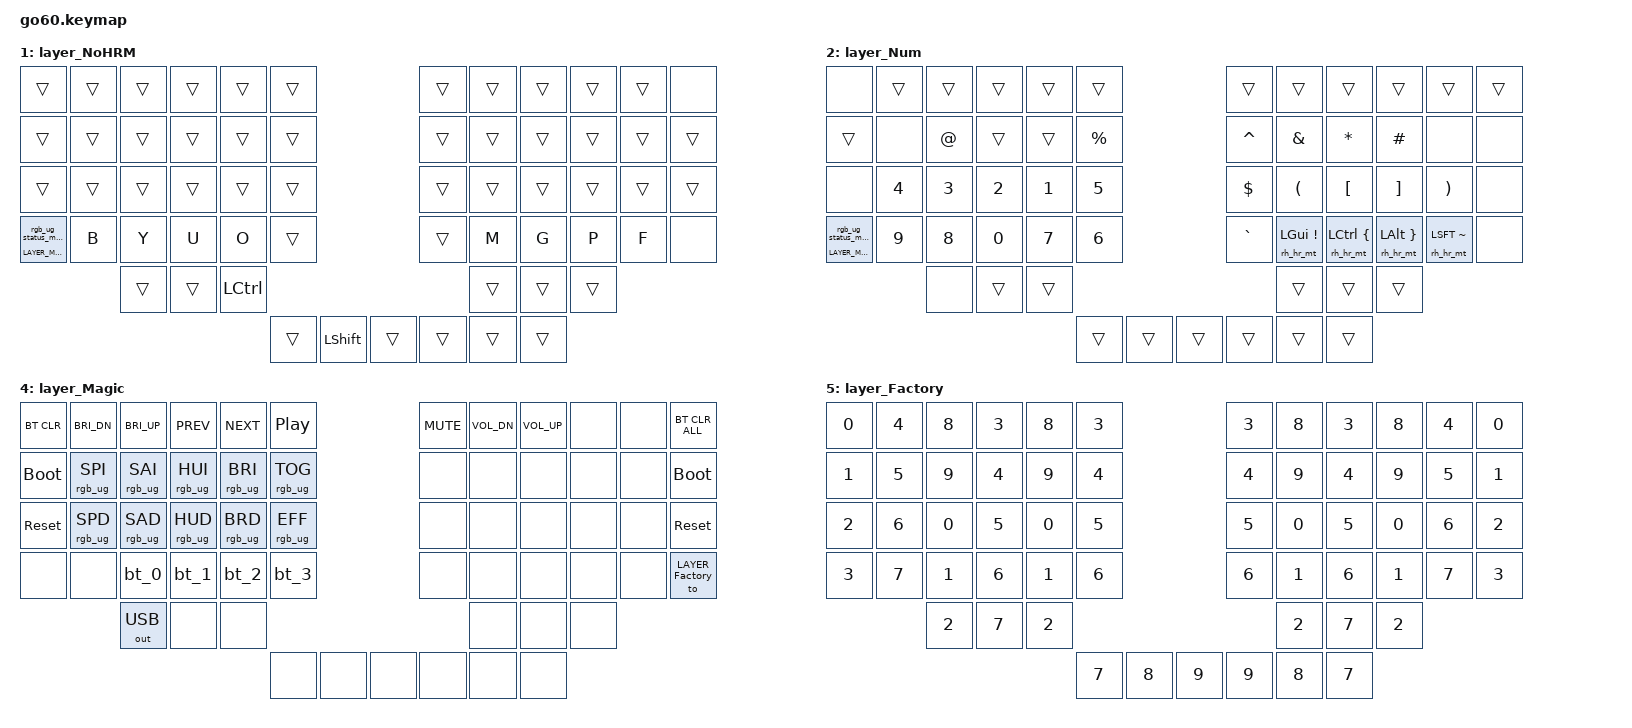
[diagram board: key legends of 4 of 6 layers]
/*
 * Copyright (c) 2020 The ZMK Contributors
 *
 * SPDX-License-Identifier: MIT
 */

#include <behaviors.dtsi>

#include <dt-bindings/zmk/bt.h>
#include <dt-bindings/zmk/ext_power.h>
#include <dt-bindings/zmk/keys.h>
#include <dt-bindings/zmk/outputs.h>
#include <dt-bindings/zmk/rgb.h>
#include <dt-bindings/zmk/input_transform.h>
#include <dt-bindings/zmk/pointing.h>

#include <input/processors.dtsi>
#include <zephyr/dt-bindings/input/input-event-codes.h>

/* Key positions */

#define POS_LH_C6R1 0
#define POS_LH_C5R1 1
#define POS_LH_C4R1 2
#define POS_LH_C3R1 3
#define POS_LH_C2R1 4
#define POS_LH_C1R1 5
#define POS_RH_C1R1 6
#define POS_RH_C2R1 7
#define POS_RH_C3R1 8
#define POS_RH_C4R1 9
#define POS_RH_C5R1 10
#define POS_RH_C6R1 11
#define POS_LH_C6R2 12
#define POS_LH_C5R2 13
#define POS_LH_C4R2 14
#define POS_LH_C3R2 15
#define POS_LH_C2R2 16
#define POS_LH_C1R2 17
#define POS_RH_C1R2 18
#define POS_RH_C2R2 19
#define POS_RH_C3R2 20
#define POS_RH_C4R2 21
#define POS_RH_C5R2 22
#define POS_RH_C6R2 23
#define POS_LH_C6R3 24
#define POS_LH_C5R3 25
#define POS_LH_C4R3 26
#define POS_LH_C3R3 27
#define POS_LH_C2R3 28
#define POS_LH_C1R3 29
#define POS_RH_C1R3 30
#define POS_RH_C2R3 31
#define POS_RH_C3R3 32
#define POS_RH_C4R3 33
#define POS_RH_C5R3 34
#define POS_RH_C6R3 35
#define POS_LH_C6R4 36
#define POS_LH_C5R4 37
#define POS_LH_C4R4 38
#define POS_LH_C3R4 39
#define POS_LH_C2R4 40
#define POS_LH_C1R4 41
#define POS_RH_C1R4 42
#define POS_RH_C2R4 43
#define POS_RH_C3R4 44
#define POS_RH_C4R4 45
#define POS_RH_C5R4 46
#define POS_RH_C6R4 47
#define POS_LH_C4R5 48
#define POS_LH_C3R5 49
#define POS_LH_C2R5 50
#define POS_RH_C2R5 51
#define POS_RH_C3R5 52
#define POS_RH_C4R5 53
#define POS_LH_T1 54
#define POS_LH_T2 55
#define POS_LH_T3 56
#define POS_RH_T3 57
#define POS_RH_T2 58
#define POS_RH_T1 59


#define LEFT_HAND_KEYS \
  POS_LH_C1R1 POS_LH_C2R1 POS_LH_C3R1 POS_LH_C4R1 POS_LH_C5R1 POS_LH_C6R1 \
  POS_LH_C1R2 POS_LH_C2R2 POS_LH_C3R2 POS_LH_C4R2 POS_LH_C5R2 POS_LH_C6R2 \
  POS_LH_C1R3 POS_LH_C2R3 POS_LH_C3R3 POS_LH_C4R3 POS_LH_C5R3 POS_LH_C6R3 \
  POS_LH_C1R4 POS_LH_C2R4 POS_LH_C3R4 POS_LH_C4R4 POS_LH_C5R4 POS_LH_C6R4 \
              POS_LH_C2R5 POS_LH_C3R5 POS_LH_C4R5

#define RIGHT_HAND_KEYS \
  POS_RH_C1R1 POS_RH_C2R1 POS_RH_C3R1 POS_RH_C4R1 POS_RH_C5R1 POS_RH_C6R1 \
  POS_RH_C1R2 POS_RH_C2R2 POS_RH_C3R2 POS_RH_C4R2 POS_RH_C5R2 POS_RH_C6R2 \
  POS_RH_C1R3 POS_RH_C2R3 POS_RH_C3R3 POS_RH_C4R3 POS_RH_C5R3 POS_RH_C6R3 \
  POS_RH_C1R4 POS_RH_C2R4 POS_RH_C3R4 POS_RH_C4R4 POS_RH_C5R4 POS_RH_C6R4 \
              POS_RH_C2R5 POS_RH_C3R5 POS_RH_C4R5

#define THUMB_KEYS \
  POS_LH_T1 POS_LH_T2 POS_LH_T3 \
  POS_RH_T1 POS_RH_T2 POS_RH_T3


// layers
#define LAYER_Base 0
#define LAYER_NoHRM 1
#define LAYER_Num 2
#define LAYER_Nav 3
#define LAYER_Magic 4
#define LAYER_Factory 5


/* Custom Defined Behaviors */
/ {
    /* How long Sticky Keys and Sticky Layers stay pressed */
#define STICKY_KEY_RELEASE_AFTER_MS 600

/* How quickly Combo keys must be pressed together */
#define COMBO_TIMEOUT_MS 45

/* How quickly both thumb Shift keys must be pressed together to activate Caps
   Word */
#define CAPS_WORD_COMBO_TIMEOUT_MS 150

/* How long to hold to activate home row mods for same side or mouse usage */
#define HOME_ROW_MODS_TAPPING_TERM_MS 300

/* Cool down after typing before home row mods can be used */
#define HOME_ROW_MODS_QUICK_TAP_MS 250

/* How long thumb keys can be held before rolls send the higher layer key */
#define THUMBS_TAPPING_TERM_MS 200

/* How quickly to double tap reaching thumb keys to hold down the tap action */
#define REACH_THUMBS_QUICK_TAP_MS 250

/* How long until each phase of the typing assist features times out */
#define TYPING_ASSIST_TIMEOUT_MS 60000

/* How long to hold for Autoshift */
#define AUTOSHIFT_TAPPING_TERM_MS 200

/* How long until the word and line selection feature times out */
#define SELECT_TIMEOUT_MS 60000

/* How quickly confirmation action keys must be double tapped to activate */
#define DOUBLE_TAP_TIMEOUT_MS 250


/* Convert NAME parameters into a ZMK label string */
#define STRINGIFY(x) #x

/* Create a ZMK Behavior without having to specify the name three times */
#define ZMK_BEHAVIOR(NAME, ...) \
    behaviors { \
        NAME: NAME { \
            label = STRINGIFY(ZB_ ## NAME); \
            __VA_ARGS__ \
        }; \
    };

/* Hold-Tap helper */
#define HOLD_TAP(NAME, ...) \
    ZMK_BEHAVIOR(NAME, \
        compatible = "zmk,behavior-hold-tap"; \
        #binding-cells = <2>; \
        __VA_ARGS__ \
    )

/* Balanced Hold-Tap for home row mods and thumb layer keys */
#define BALANCED_HOLD_TAP(NAME, ...) \
    HOLD_TAP(NAME, \
        flavor = "balanced";  /* Fast hold */ \
        __VA_ARGS__ \
    )

/* "Timerless" home row mod Hold-Tap using defined timers */
#define HOME_ROW_MOD_HELPER(NAME, KEY_POSITIONS, TAP) \
    BALANCED_HOLD_TAP(NAME, \
        tapping-term-ms = <HOME_ROW_MODS_TAPPING_TERM_MS>;  /* Mouse usage */ \
        quick-tap-ms = <HOME_ROW_MODS_QUICK_TAP_MS>;  /* Typing cool down */ \
        require-prior-idle-ms = <150>; \
        hold-trigger-key-positions = <KEY_POSITIONS>;  /* Use other hand */ \
        hold-trigger-on-release; \
        bindings = <&kp>, <TAP>; \
    )

/* Left and right hand home row mods */
#define HOME_ROW_MOD_LH(NAME, TAP) \
    HOME_ROW_MOD_HELPER(NAME, RIGHT_HAND_KEYS THUMB_KEYS, TAP)
#define HOME_ROW_MOD_RH(NAME, TAP) \
    HOME_ROW_MOD_HELPER(NAME, LEFT_HAND_KEYS THUMB_KEYS, TAP)

HOME_ROW_MOD_LH(lh_hr_mt, &kp)  /* Left hand */
HOME_ROW_MOD_RH(rh_hr_mt, &kp)  /* Right hand */


/* Home thumb layer tap without quick tap; faster layer switching */
#define HOME_THUMB_LAYER_TAP(NAME, TAP_BINDING) \
    BALANCED_HOLD_TAP(NAME, \
        tapping-term-ms = <THUMBS_TAPPING_TERM_MS>;  /* Rolls send tap key */ \
        bindings = <&mo>, <TAP_BINDING>; \
    )

/* Reaching thumb layer tap with double tap to repeat */
#define REACH_THUMB_LAYER_TAP(NAME, TAP_BINDING) \
    BALANCED_HOLD_TAP(NAME, \
        tapping-term-ms = <THUMBS_TAPPING_TERM_MS>;  /* Rolls send tap key */ \
        quick-tap-ms = <REACH_THUMBS_QUICK_TAP_MS>;  /* Double tap repeats */ \
        bindings = <&mo>, <TAP_BINDING>; \
    )

HOME_THUMB_LAYER_TAP(ht_lt, &kp)  /* Used for Editing and Numbers layers */
REACH_THUMB_LAYER_TAP(rt_lt, &kp)  /* Used for Media and Function layers */

};

#define HRML(k1,k2,k3,k4) &lh_hr_mt LSHFT k1 &lh_hr_mt LALT k2 &lh_hr_mt LCTRL k3 &lh_hr_mt LGUI k4
#define HRMR(k1,k2,k3,k4) &rh_hr_mt LGUI k1 &rh_hr_mt LCTRL k2 &rh_hr_mt LALT k3 &rh_hr_mt LSHFT k4

#define PTAB &kp LC(LS(TAB))
#define NTAB &kp LC(TAB)
#define VOL_U &kp C_VOL_UP
#define VOL_D &kp C_VOL_DN

#define NAVRET &ht_lt LAYER_Nav ENTER
#define NUMESC &ht_lt LAYER_Num ESC
#define NUMSPC &rt_lt LAYER_Num SPACE
#define NUMBSP &rt_lt LAYER_Num BSPC
#define NAVR &rt_lt LAYER_Nav R

#define CLBRC &rh_hr_mt LCTL LBRC
#define ARBRC &rh_hr_mt LALT RBRC
#define GEXCL &rh_hr_mt LGUI EXCL
#define STILDE &rh_hr_mt LSFT TILDE

/ {
    combos {
        compatible = "zmk,combos";

        combo_exclamation {
            key-positions = <POS_LH_C5R1 POS_LH_C5R2>;
            bindings = <&kp EXCLAMATION>;
        };

        combo_at {
            key-positions = <POS_LH_C4R2 POS_LH_C4R1>;
            bindings = <&kp AT>;
        };

        combo_hash {
            key-positions = <POS_LH_C3R2 POS_LH_C3R1>;
            bindings = <&kp HASH>;
        };

        combo_dollar {
            key-positions = <POS_LH_C2R2 POS_LH_C2R1>;
            bindings = <&kp DOLLAR>;
        };

        combo_percent {
            key-positions = <POS_LH_C1R2 POS_LH_C1R1>;
            bindings = <&kp PERCENT>;
        };

        combo_caret {
            key-positions = <POS_RH_C1R2 POS_RH_C1R1>;
            bindings = <&kp CARET>;
        };

        combo_ampersand {
            key-positions = <POS_RH_C2R1 POS_RH_C2R2>;
            bindings = <&kp AMPERSAND>;
        };

        combo_star {
            key-positions = <POS_RH_C3R1 POS_RH_C3R2>;
            bindings = <&kp STAR>;
        };

        combo_tab {
            key-positions = <POS_RH_C2R3 POS_RH_C2R4>;
            bindings = <&kp TAB>;
        };

        combo_grave {
            key-positions = <POS_RH_C4R1 POS_RH_C4R2>;
            bindings = <&kp GRAVE>;
        };

        combo_tilde {
            key-positions = <POS_RH_C5R1 POS_RH_C5R2>;
            bindings = <&kp TILDE>;
        };

        /*
        combo_ {
            key-positions = <POS_RH_C4R1 POS_RH_C4R2>;
            bindings = <&kp F9>;
        };

        combo_F10_cb_v1_TKZ {
            key-positions = <POS_RH_C5R1 POS_RH_C5R2>;
            bindings = <&kp F10>;
        };

        combo_F11_cb_v1_TKZ {
            key-positions = <POS_RH_C6R1 POS_RH_C6R2>;
            bindings = <&kp F11>;
        };

        combo_F12_cb_v1_TKZ {
            key-positions = <POS_RH_C6R1 POS_RH_C5R1>;
            bindings = <&kp F12>;
        };
        */
    };
};

/ {
    input_processors {
        zip_click_to_right_click_mapper: zip_click_to_right_click_mapper {
            compatible = "zmk,input-processor-code-mapper";
            #input-processor-cells = <0>;
            type = <INPUT_EV_KEY>;
            map = <INPUT_BTN_0 INPUT_BTN_1>;
        };
    };

    behaviors {
        magic: magic {
            compatible = "zmk,behavior-hold-tap";
            #binding-cells = <2>;
            flavor = "tap-preferred";
            tapping-term-ms = <200>;
            bindings = <&mo>, <&rgb_ug_status_macro>;
        };

        bt_0: bt_0 {
            compatible = "zmk,behavior-tap-dance";
            #binding-cells = <0>;
            tapping-term-ms = <200>;
            bindings = <&bt_select_0>, <&bt BT_DISC 0>;
        };
        bt_1: bt_1 {
            compatible = "zmk,behavior-tap-dance";
            #binding-cells = <0>;
            tapping-term-ms = <200>;
            bindings = <&bt_select_1>, <&bt BT_DISC 1>;
        };
        bt_2: bt_2 {
            compatible = "zmk,behavior-tap-dance";
            #binding-cells = <0>;
            tapping-term-ms = <200>;
            bindings = <&bt_select_2>, <&bt BT_DISC 2>;
        };
        bt_3: bt_3 {
            compatible = "zmk,behavior-tap-dance";
            #binding-cells = <0>;
            tapping-term-ms = <200>;
            bindings = <&bt_select_3>, <&bt BT_DISC 3>;
        };
    };

    macros {
        rgb_ug_status_macro: rgb_ug_status_macro {
            compatible = "zmk,behavior-macro";
            #binding-cells = <0>;
            bindings = <&rgb_ug RGB_STATUS>;
        };

        bt_select_0: bt_select_0 {
            compatible = "zmk,behavior-macro";
            #binding-cells = <0>;
            bindings
                = <&out OUT_BLE>,
                  <&bt BT_SEL 0>;
        };
        bt_select_1: bt_select_1 {
            compatible = "zmk,behavior-macro";
            #binding-cells = <0>;
            bindings
                = <&out OUT_BLE>,
                  <&bt BT_SEL 1>;
        };
        bt_select_2: bt_select_2 {
            compatible = "zmk,behavior-macro";
            #binding-cells = <0>;
            bindings
                = <&out OUT_BLE>,
                  <&bt BT_SEL 2>;
        };
        bt_select_3: bt_select_3 {
            compatible = "zmk,behavior-macro";
            #binding-cells = <0>;
            bindings
                = <&out OUT_BLE>,
                  <&bt BT_SEL 3>;
        };
    };

    keymap {
        compatible = "zmk,keymap";
        layer_Base {
            bindings = <
            &kp GRAVE   &kp N1     &kp N2  &kp N3    &kp N4  &kp N5                                                      &kp N6    &kp N7     &kp N8    &kp N9    &kp N0       &none
              &kp TAB   &kp SQT    &kp X   &kp COMMA &kp DOT &kp EQUAL                                                   &kp FSLH  &kp L      &kp D     &kp W     &kp V        &kp BSLH
              &kp Q     &kp C      &kp I   &kp E     &kp A   &kp MINUS                                                   &kp K     &kp H      &kp T     &kp N     &kp S        &kp Z
 &magic LAYER_Magic 0   HRML(B,    Y,      U,        O)      &kp SEMI                                                    &kp J     HRMR(M,    G,        P,        F)           &none
                               &kp LPAR    &kp RPAR  &sk LCTL                                                                      &sk LALT   &kp LBKT  &kp RBKT
                                                             NAVRET  &sk LSHFT  NUMESC              NUMBSP  &kp SPACE  NAVR
            >;
        };

        layer_NoHRM {
            bindings = <
               &trans  &trans  &trans  &trans  &trans  &trans                                                           &trans  &trans  &trans  &trans  &trans  &none
               &trans  &trans  &trans  &trans  &trans  &trans                                                           &trans  &trans  &trans  &trans  &trans  &trans
               &trans  &trans  &trans  &trans  &trans  &trans                                                           &trans  &trans  &trans  &trans  &trans  &trans
 &magic LAYER_Magic 0  &kp B   &kp Y   &kp U   &kp O   &trans                                                           &trans  &kp M   &kp G   &kp P   &kp F   &none
                               &trans  &trans  &kp LCTL                                                                         &trans  &trans  &trans
                                                       &trans  &kp LSHFT &trans                           &trans  &trans  &trans
            >;
        };

        layer_Num {
            bindings = <
                &none     &trans     &trans     &trans     &trans       &trans                                              &trans     &trans     &trans     &trans         &trans      &trans
               &trans      &none     &kp AT     &trans     &trans       &kp PRCNT                                           &kp CARET  &kp AMPS   &kp STAR   &kp HASH       &none       &none
               &none      &kp N4     &kp N3     &kp N2     &kp N1       &kp N5                                              &kp DLLR   &kp LPAR   &kp LBKT   &kp RBKT       &kp RPAR    &none
 &magic LAYER_Magic 0     &kp N9     &kp N8     &kp N0     &kp N7       &kp N6                                              &kp GRAVE  GEXCL      CLBRC      ARBRC          STILDE      &none
                                      &none     &trans     &trans                                                                      &trans     &trans     &trans
                                                                        &trans  &trans  &trans              &trans  &trans  &trans
            >;
        };

        layer_Nav {
            bindings = <
               &none        &kp F1    &kp F2     &kp F3    &kp F4      &kp F5                                                 &kp F6     &kp F7     &kp F8     &kp F9         &kp F10     &kp F11
               &trans        &none    VOL_U      VOL_D     &kp END     &kp PG_UP                                              &none      &kp LC(R)  PTAB       NTAB           &none       &kp F12
               &trans    &kp LC(Y)    &kp LEFT   &kp DOWN  &kp RIGHT   &kp PG_DN                                              &none      &kp LEFT   &kp DOWN   &kp UP         &kp RIGHT   &none
 &magic LAYER_Magic 0 HRML(C_PREV,    C_MUTE,    C_PP,     C_NEXT)     &none                                                  &kp X      &kp HOME   &kp PG_DN  &kp PG_UP      &kp END     &none
                                      &trans     &trans    &trans                                                                        &trans     &trans     &trans
                                                                       &trans  &trans  &trans              &kp BSPC  &to LAYER_Base  &to LAYER_NoHRM
            >;
        };

        layer_Magic {
            bindings = <
  &bt BT_CLR     &kp C_BRI_DN     &kp C_BRI_UP       &kp C_PREV       &kp C_NEXT         &kp C_PP                                &kp C_MUTE  &kp C_VOL_DN  &kp C_VOL_UP   &none   &none    &bt BT_CLR_ALL
 &bootloader  &rgb_ug RGB_SPI  &rgb_ug RGB_SAI  &rgb_ug RGB_HUI  &rgb_ug RGB_BRI  &rgb_ug RGB_TOG                                     &none         &none         &none   &none   &none       &bootloader
  &sys_reset  &rgb_ug RGB_SPD  &rgb_ug RGB_SAD  &rgb_ug RGB_HUD  &rgb_ug RGB_BRD  &rgb_ug RGB_EFF                                     &none         &none         &none   &none   &none        &sys_reset
       &none            &none            &bt_0            &bt_1            &bt_2            &bt_3                                     &none         &none         &none   &none   &none &to LAYER_Factory
                                  &out OUT_USB            &none            &none                                                                    &none         &none   &none
                                                                                            &none   &none   &none     &none   &none   &none
            >;
        };

        layer_Factory {
            bindings = <
 &kp N0  &kp N4  &kp N8  &kp N3  &kp N8  &kp N3                                       &kp N3  &kp N8  &kp N3  &kp N8  &kp N4  &kp N0
 &kp N1  &kp N5  &kp N9  &kp N4  &kp N9  &kp N4                                       &kp N4  &kp N9  &kp N4  &kp N9  &kp N5  &kp N1
 &kp N2  &kp N6  &kp N0  &kp N5  &kp N0  &kp N5                                       &kp N5  &kp N0  &kp N5  &kp N0  &kp N6  &kp N2
 &kp N3  &kp N7  &kp N1  &kp N6  &kp N1  &kp N6                                       &kp N6  &kp N1  &kp N6  &kp N1  &kp N7  &kp N3
                 &kp N2  &kp N7  &kp N2                                                       &kp N2  &kp N7  &kp N2
                                          &kp N7  &kp N8  &kp N9      &kp N9  &kp N8  &kp N7
            >;
        };
    };
};

&cirque_rh_listener {
    input-processors = <&zip_xy_scaler 7 3>;
    layer_2 {
        layers = <2>;
        input-processors = <&zip_xy_scaler 9 1>;
    };
};

&cirque_lh_listener {
    input-processors = <&zip_xy_to_scroll_mapper>, <&zip_scroll_scaler 1 9>, <&zip_click_to_right_click_mapper>;
    layer_4 {
        layers = <4>;
        input-processors = <&zip_xy_scaler 3 1>;
    };
};
